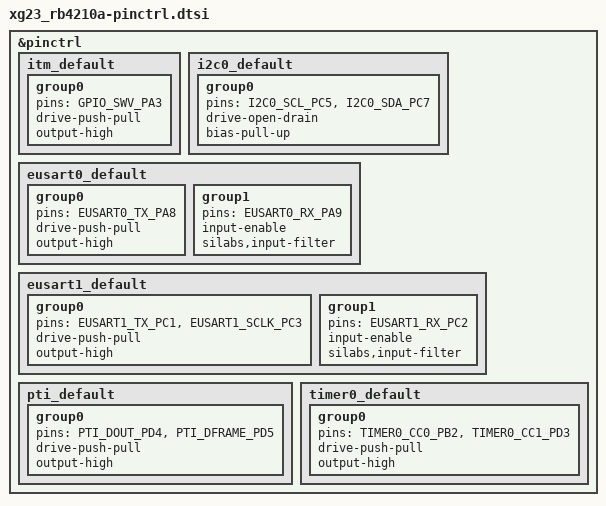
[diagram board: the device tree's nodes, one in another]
/*
 * Copyright (c) 2024 Yishai Jaffe
 *
 * SPDX-License-Identifier: Apache-2.0
 */

#include <zephyr/dt-bindings/pinctrl/silabs/xg23-pinctrl.h>

&pinctrl {
	itm_default: itm_default {
		group0 {
			pins = <GPIO_SWV_PA3>;
			drive-push-pull;
			output-high;
		};
	};

	i2c0_default: i2c0_default {
		group0 {
			pins = <I2C0_SCL_PC5>, <I2C0_SDA_PC7>;
			drive-open-drain;
			bias-pull-up;
		};
	};

	eusart0_default: eusart0_default {
		group0 {
			pins = <EUSART0_TX_PA8>;
			drive-push-pull;
			output-high;
		};

		group1 {
			pins = <EUSART0_RX_PA9>;
			input-enable;
			silabs,input-filter;
		};
	};

	eusart1_default: eusart1_default {
		group0 {
			pins = <EUSART1_TX_PC1>, <EUSART1_SCLK_PC3>;
			drive-push-pull;
			output-high;
		};

		group1 {
			pins = <EUSART1_RX_PC2>;
			input-enable;
			silabs,input-filter;
		};
	};

	pti_default: pti_default {
		group0 {
			pins = <PTI_DOUT_PD4>, <PTI_DFRAME_PD5>;
			drive-push-pull;
			output-high;
		};
	};

	timer0_default: timer0_default {
		group0 {
			pins = <TIMER0_CC0_PB2>, <TIMER0_CC1_PD3>;
			drive-push-pull;
			output-high;
		};
	};
};
